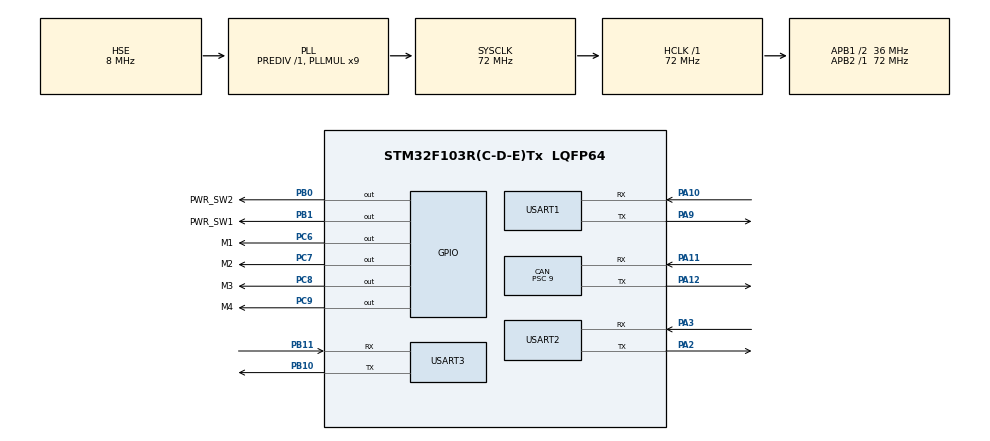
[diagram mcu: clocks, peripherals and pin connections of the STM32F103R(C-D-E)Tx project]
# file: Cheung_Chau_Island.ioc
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CAN.BS1=CAN_BS1_4TQ
CAN.BS2=CAN_BS2_3TQ
CAN.CalculateBaudRate=500000
CAN.CalculateTimeBit=2000
CAN.CalculateTimeQuantum=250.0
CAN.Prescaler=9
CAN.SJW=CAN_SJW_1TQ
Dma.Request0=USART1_RX
Dma.Request1=USART1_TX
Dma.Request2=USART3_RX
Dma.USART1_RX.0.Direction=DMA_PERIPH_TO_MEMORY
Dma.USART1_RX.0.Instance=DMA1_Channel5
Dma.USART1_RX.0.MemDataAlignment=DMA_MDATAALIGN_BYTE
Dma.USART1_RX.0.MemInc=DMA_MINC_ENABLE
Dma.USART1_RX.0.Mode=DMA_CIRCULAR
Dma.USART1_RX.0.PeriphDataAlignment=DMA_PDATAALIGN_BYTE
Dma.USART1_RX.0.PeriphInc=DMA_PINC_DISABLE
Dma.USART1_RX.0.Priority=DMA_PRIORITY_LOW
Dma.USART1_TX.1.Direction=DMA_MEMORY_TO_PERIPH
Dma.USART1_TX.1.Instance=DMA1_Channel4
Dma.USART1_TX.1.MemDataAlignment=DMA_MDATAALIGN_BYTE
Dma.USART1_TX.1.MemInc=DMA_MINC_ENABLE
Dma.USART1_TX.1.Mode=DMA_NORMAL
Dma.USART1_TX.1.PeriphDataAlignment=DMA_PDATAALIGN_BYTE
Dma.USART1_TX.1.PeriphInc=DMA_PINC_DISABLE
Dma.USART1_TX.1.Priority=DMA_PRIORITY_LOW
Dma.USART3_RX.2.Direction=DMA_PERIPH_TO_MEMORY
Dma.USART3_RX.2.Instance=DMA1_Channel3
Dma.USART3_RX.2.MemDataAlignment=DMA_MDATAALIGN_BYTE
Dma.USART3_RX.2.MemInc=DMA_MINC_ENABLE
Dma.USART3_RX.2.Mode=DMA_CIRCULAR
Dma.USART3_RX.2.PeriphDataAlignment=DMA_PDATAALIGN_BYTE
Dma.USART3_RX.2.PeriphInc=DMA_PINC_DISABLE
Dma.USART3_RX.2.Priority=DMA_PRIORITY_LOW
FREERTOS.Tasks01=system_service,24,256,system_service_task,As weak,NULL,Dynamic,NULL,NULL
FREERTOS.configTOTAL_HEAP_SIZE=10240
Mcu.Family=STM32F1
Mcu.Name=STM32F103R(C-D-E)Tx
Mcu.Package=LQFP64
NVIC.CAN1_RX1_IRQn=true\:5\:0\:false\:false\:true\:true\:true\:true\:true
NVIC.CAN1_SCE_IRQn=true\:5\:0\:false\:false\:true\:true\:true\:true\:true
NVIC.DMA1_Channel3_IRQn=true\:5\:0\:false\:false\:true\:true\:false\:true\:true
NVIC.DMA1_Channel4_IRQn=true\:5\:0\:false\:false\:true\:true\:false\:true\:true
NVIC.DMA1_Channel5_IRQn=true\:5\:0\:false\:false\:true\:true\:false\:true\:true
NVIC.PriorityGroup=NVIC_PRIORITYGROUP_4
NVIC.TIM7_IRQn=true\:15\:0\:false\:false\:true\:false\:false\:true\:true
NVIC.TimeBase=TIM7_IRQn
NVIC.TimeBaseIP=TIM7
NVIC.USART1_IRQn=true\:5\:0\:true\:false\:true\:true\:true\:true\:true
NVIC.USART3_IRQn=true\:5\:0\:true\:false\:true\:true\:true\:true\:true
NVIC.USB_HP_CAN1_TX_IRQn=true\:5\:0\:false\:false\:true\:true\:true\:true\:true
NVIC.USB_LP_CAN1_RX0_IRQn=true\:5\:0\:false\:false\:true\:true\:true\:true\:true
PA10.Mode=Asynchronous
PA10.Signal=USART1_RX
PA11.Mode=CAN_Activate
PA11.Signal=CAN_RX
PA12.Mode=CAN_Activate
PA12.Signal=CAN_TX
PA13.Mode=Serial_Wire
PA13.Signal=SYS_JTMS-SWDIO
PA14.Mode=Serial_Wire
PA14.Signal=SYS_JTCK-SWCLK
PA2.Mode=Asynchronous
PA2.Signal=USART2_TX
PA3.Mode=Asynchronous
PA3.Signal=USART2_RX
PA9.Mode=Asynchronous
PA9.Signal=USART1_TX
PB0.GPIO_Label=PWR_SW2
PB0.GPIO_Speed=GPIO_SPEED_FREQ_HIGH
PB0.Signal=GPIO_Output
PB1.GPIO_Label=PWR_SW1
PB1.GPIO_Speed=GPIO_SPEED_FREQ_HIGH
PB1.Signal=GPIO_Output
PB10.Mode=Asynchronous
PB10.Signal=USART3_TX
PB11.Mode=Asynchronous
PB11.Signal=USART3_RX
PC14-OSC32_IN.Mode=LSE-External-Oscillator
PC14-OSC32_IN.Signal=RCC_OSC32_IN
PC15-OSC32_OUT.Mode=LSE-External-Oscillator
PC15-OSC32_OUT.Signal=RCC_OSC32_OUT
PC6.GPIO_Label=M1
PC6.GPIO_Speed=GPIO_SPEED_FREQ_HIGH
PC6.Signal=GPIO_Output
PC7.GPIO_Label=M2
PC7.GPIO_Speed=GPIO_SPEED_FREQ_HIGH
PC7.Signal=GPIO_Output
PC8.GPIO_Label=M3
PC8.GPIO_Speed=GPIO_SPEED_FREQ_HIGH
PC8.Signal=GPIO_Output
PC9.GPIO_Label=M4
PC9.GPIO_Speed=GPIO_SPEED_FREQ_HIGH
PC9.Signal=GPIO_Output
PD0-OSC_IN.Mode=HSE-External-Oscillator
PD0-OSC_IN.Signal=RCC_OSC_IN
PD1-OSC_OUT.Mode=HSE-External-Oscillator
PD1-OSC_OUT.Signal=RCC_OSC_OUT
ProjectManager.HeapSize=0x200
ProjectManager.StackSize=0x400
ProjectManager.TargetToolchain=MDK-ARM V5.32
RCC.AHBFreq_Value=72000000
RCC.APB1CLKDivider=RCC_HCLK_DIV2
RCC.APB1Freq_Value=36000000
RCC.APB1TimFreq_Value=72000000
RCC.APB2Freq_Value=72000000
RCC.APB2TimFreq_Value=72000000
RCC.HCLKFreq_Value=72000000
RCC.PLLMUL=RCC_PLL_MUL9
RCC.PLLSourceVirtual=RCC_PLLSOURCE_HSE
RCC.SYSCLKFreq_VALUE=72000000
RCC.SYSCLKSource=RCC_SYSCLKSOURCE_PLLCLK
RCC.USBFreq_Value=72000000
USART1.VirtualMode=VM_ASYNC
USART2.VirtualMode=VM_ASYNC
USART3.VirtualMode=VM_ASYNC
VP_FREERTOS_VS_CMSIS_V2.Mode=CMSIS_V2
VP_SYS_VS_tim7.Mode=TIM7
board=custom

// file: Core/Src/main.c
/* USER CODE BEGIN Header */
/**
  ******************************************************************************
  * @file           : main.c
  * @brief          : Main program body
  ******************************************************************************
  * @attention
  *
  * Copyright (c) 2024 STMicroelectronics.
  * All rights reserved.
  *
  * This software is licensed under terms that can be found in the LICENSE file
  * in the root directory of this software component.
  * If no LICENSE file comes with this software, it is provided AS-IS.
  *
  ******************************************************************************
  */
/* USER CODE END Header */
#include "main.h"
#include "cmsis_os.h"
#include "can.h"
#include "dma.h"
#include "usart.h"
#include "gpio.h"

/* USER CODE BEGIN Includes */
#include "init.h"
/* USER CODE END Includes */

void SystemClock_Config(void);
void MX_FREERTOS_Init(void);

int main(void)
{

  /* MCU Configuration--------------------------------------------------------*/

  /* Reset of all peripherals, Initializes the Flash interface and the Systick. */
  HAL_Init();

  /* Configure the system clock */
  SystemClock_Config();

  /* Initialize all configured peripherals */
  MX_GPIO_Init();
  MX_DMA_Init();
  MX_USART1_UART_Init();
  MX_USART2_UART_Init();
  MX_USART3_UART_Init();
  MX_CAN_Init();

  /* Init scheduler */
  osKernelInitialize();

  /* Call init function for freertos objects (in freertos.c) */
  MX_FREERTOS_Init();

  /* Start scheduler */
  osKernelStart();

  /* We should never get here as control is now taken by the scheduler */
  /* Infinite loop */
  while (1)
  {

  }
}

void SystemClock_Config(void)
{
  RCC_OscInitTypeDef RCC_OscInitStruct = {0};
  RCC_ClkInitTypeDef RCC_ClkInitStruct = {0};

  /** Initializes the RCC Oscillators according to the specified parameters
  * in the RCC_OscInitTypeDef structure.
  */
  RCC_OscInitStruct.OscillatorType = RCC_OSCILLATORTYPE_HSE;
  RCC_OscInitStruct.HSEState = RCC_HSE_ON;
  RCC_OscInitStruct.HSEPredivValue = RCC_HSE_PREDIV_DIV1;
  RCC_OscInitStruct.HSIState = RCC_HSI_ON;
  RCC_OscInitStruct.PLL.PLLState = RCC_PLL_ON;
  RCC_OscInitStruct.PLL.PLLSource = RCC_PLLSOURCE_HSE;
  RCC_OscInitStruct.PLL.PLLMUL = RCC_PLL_MUL9;
  if (HAL_RCC_OscConfig(&RCC_OscInitStruct) != HAL_OK)
  {
    Error_Handler();
  }

  /** Initializes the CPU, AHB and APB buses clocks
  */
  RCC_ClkInitStruct.ClockType = RCC_CLOCKTYPE_HCLK|RCC_CLOCKTYPE_SYSCLK
                              |RCC_CLOCKTYPE_PCLK1|RCC_CLOCKTYPE_PCLK2;
  RCC_ClkInitStruct.SYSCLKSource = RCC_SYSCLKSOURCE_PLLCLK;
  RCC_ClkInitStruct.AHBCLKDivider = RCC_SYSCLK_DIV1;
  RCC_ClkInitStruct.APB1CLKDivider = RCC_HCLK_DIV2;
  RCC_ClkInitStruct.APB2CLKDivider = RCC_HCLK_DIV1;

  if (HAL_RCC_ClockConfig(&RCC_ClkInitStruct, FLASH_LATENCY_2) != HAL_OK)
  {
    Error_Handler();
  }
}

void HAL_TIM_PeriodElapsedCallback(TIM_HandleTypeDef *htim)
{
  if (htim->Instance == TIM7) {
    HAL_IncTick();
  }
}

void Error_Handler(void)
{
  __disable_irq();
  while (1)
  {
  }
}

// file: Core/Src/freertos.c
/* USER CODE BEGIN Header */
/**
  ******************************************************************************
  * File Name          : freertos.c
  * Description        : Code for freertos applications
  ******************************************************************************
  * @attention
  *
  * Copyright (c) 2024 STMicroelectronics.
  * All rights reserved.
  *
  * This software is licensed under terms that can be found in the LICENSE file
  * in the root directory of this software component.
  * If no LICENSE file comes with this software, it is provided AS-IS.
  *
  ******************************************************************************
  */
/* USER CODE END Header */

#include "FreeRTOS.h"
#include "task.h"
#include "main.h"
#include "cmsis_os.h"

/* Definitions for system_service */
osThreadId_t system_serviceHandle;
const osThreadAttr_t system_service_attributes = {
  .name = "system_service",
  .stack_size = 256 * 4,
  .priority = (osPriority_t) osPriorityNormal,
};

void system_service_task(void *argument);

void MX_FREERTOS_Init(void); /* (MISRA C 2004 rule 8.1) */

void MX_FREERTOS_Init(void) {

  /* Create the thread(s) */
  /* creation of system_service */
  system_serviceHandle = osThreadNew(system_service_task, NULL, &system_service_attributes);

}

__weak void system_service_task(void *argument)
{
  for(;;)
  {
    osDelay(1);
  }
}
